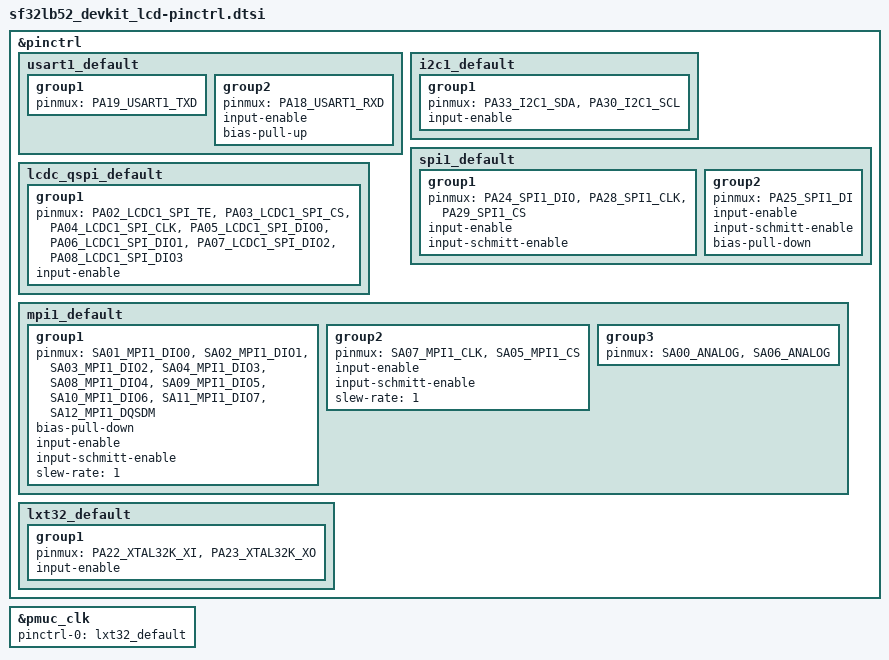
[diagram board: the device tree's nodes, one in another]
/*
 * Copyright (c) 2025 Core Devices LLC
 * Copyright (c) 2025 SiFli Technologies(Nanjing) Co., Ltd
 * SPDX-License-Identifier: Apache-2.0
 */

#include <zephyr/dt-bindings/pinctrl/sf32lb52x-pinctrl.h>

&pinctrl {
	usart1_default: usart1_default {
		group1 {
			pinmux = <PA19_USART1_TXD>;
		};

		group2 {
			pinmux = <PA18_USART1_RXD>;
			input-enable;
			bias-pull-up;
		};
	};

	i2c1_default: i2c1_default {
		group1 {
			pinmux = <PA33_I2C1_SDA>, <PA30_I2C1_SCL>;
			input-enable;
		};
	};

	spi1_default: spi1_default {
		group1 {
			pinmux = <PA24_SPI1_DIO>, <PA28_SPI1_CLK>, <PA29_SPI1_CS>;
			input-enable;
			input-schmitt-enable;
		};

		group2 {
			pinmux = <PA25_SPI1_DI>;
			input-enable;
			input-schmitt-enable;
			bias-pull-down;
		};
	};

	lcdc_qspi_default: lcdc_qspi_default {
		group1 {
			pinmux = <PA02_LCDC1_SPI_TE>,
				 <PA03_LCDC1_SPI_CS>,
				 <PA04_LCDC1_SPI_CLK>,
				 <PA05_LCDC1_SPI_DIO0>,
				 <PA06_LCDC1_SPI_DIO1>,
				 <PA07_LCDC1_SPI_DIO2>,
				 <PA08_LCDC1_SPI_DIO3>;
			input-enable;
		};
	};

	/* MPI1 OPI PSRAM pinmux configuration */
	mpi1_default: mpi1_default {
		group1 {
			pinmux = <SA01_MPI1_DIO0>, <SA02_MPI1_DIO1>,
				 <SA03_MPI1_DIO2>, <SA04_MPI1_DIO3>,
				 <SA08_MPI1_DIO4>, <SA09_MPI1_DIO5>,
				 <SA10_MPI1_DIO6>, <SA11_MPI1_DIO7>,
				 <SA12_MPI1_DQSDM>;
			bias-pull-down;
			input-enable;
			input-schmitt-enable;
			slew-rate=<1>;
		};

		group2 {
			pinmux = <SA07_MPI1_CLK>, <SA05_MPI1_CS>;
			input-enable;
			input-schmitt-enable;
			slew-rate=<1>;
		};

		/* SA00 and SA06 are power supply pins, configure as analog */
		group3 {
			pinmux = <SA00_ANALOG>, <SA06_ANALOG>;
		};
	};

	lxt32_default: lxt32_default {
		group1 {
			pinmux = <PA22_XTAL32K_XI>, <PA23_XTAL32K_XO>;
			input-enable;
		};
	};
};

&pmuc_clk {
	pinctrl-0 = <&lxt32_default>;
	pinctrl-names = "default";
};
